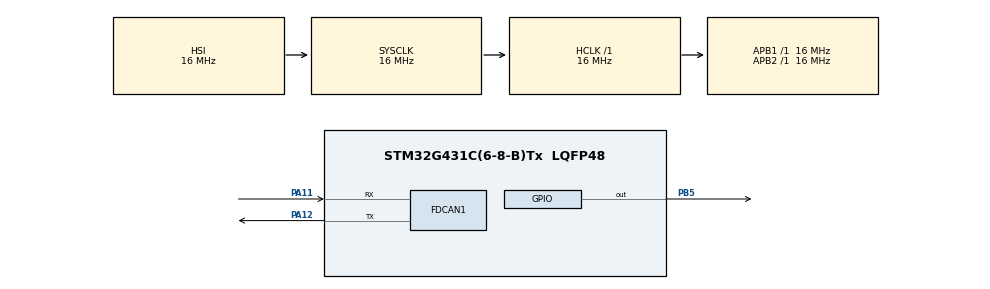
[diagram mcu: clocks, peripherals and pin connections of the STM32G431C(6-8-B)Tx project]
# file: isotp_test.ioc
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FDCAN1.AutoRetransmission=ENABLE
FDCAN1.CalculateBaudRateNominal=500000
FDCAN1.CalculateTimeBitNominal=2000
FDCAN1.CalculateTimeQuantumNominal=62.5
FDCAN1.DataSyncJumpWidth=15
FDCAN1.DataTimeSeg1=16
FDCAN1.DataTimeSeg2=15
FDCAN1.NominalPrescaler=1
FDCAN1.NominalSyncJumpWidth=2
FDCAN1.NominalTimeSeg1=29
FDCAN1.NominalTimeSeg2=2
Mcu.Family=STM32G4
Mcu.Name=STM32G431C(6-8-B)Tx
Mcu.Package=LQFP48
NVIC.FDCAN1_IT0_IRQn=true\:0\:0\:false\:false\:true\:true\:true\:true
NVIC.PriorityGroup=NVIC_PRIORITYGROUP_4
PA11.Mode=FDCAN_Activate
PA11.Signal=FDCAN1_RX
PA12.Mode=FDCAN_Activate
PA12.Signal=FDCAN1_TX
PB5.Signal=GPIO_Output
ProjectManager.HeapSize=0x200
ProjectManager.StackSize=0x400
ProjectManager.TargetToolchain=CMake
RCC.AHBFreq_Value=16000000
RCC.APB1Freq_Value=16000000
RCC.APB1TimFreq_Value=16000000
RCC.APB2Freq_Value=16000000
RCC.APB2TimFreq_Value=16000000
RCC.CortexFreq_Value=16000000
RCC.EXTERNAL_CLOCK_VALUE=12288000
RCC.HCLKFreq_Value=16000000
RCC.HSE_VALUE=8000000
RCC.HSI48_VALUE=48000000
RCC.HSI_VALUE=16000000
RCC.LSE_VALUE=32768
RCC.SYSCLKFreq_VALUE=16000000
RCC.USBFreq_Value=64000000
RCC.VCOOutputFreq_Value=128000000
VP_SYS_VS_DBSignals.Mode=DisableDeadBatterySignals
board=custom

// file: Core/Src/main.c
/* USER CODE BEGIN Header */
/**
  ******************************************************************************
  * @file           : main.c
  * @brief          : Main program body
  ******************************************************************************
  * @attention
  *
  * Copyright (c) 2026 STMicroelectronics.
  * All rights reserved.
  *
  * This software is licensed under terms that can be found in the LICENSE file
  * in the root directory of this software component.
  * If no LICENSE file comes with this software, it is provided AS-IS.
  *
  ******************************************************************************
  */
/* USER CODE END Header */
#include "main.h"
#include "fdcan.h"
#include "gpio.h"

/* USER CODE BEGIN Includes */
#include <string.h>
#include "drivers/can_driver.h"
#include "drivers/isotp.h"
#include "drivers/flash_driver.h"
#include "config/can_config.h"
#include "config/errno.h"
/* USER CODE END Includes */

void SystemClock_Config(void);

int main(void)
{

  /* MCU Configuration--------------------------------------------------------*/

  /* Reset of all peripherals, Initializes the Flash interface and the Systick. */
  HAL_Init();

  /* Configure the system clock */
  SystemClock_Config();

  /* Initialize all configured peripherals */
  MX_GPIO_Init();
  MX_FDCAN1_Init();
  /* USER CODE BEGIN 2 */

  // ================= initialise the stack
    sr_errno_t retval;
    sr_fdcan_handle_t fd_handle1;

    sr_fdcan_config_t cfg = {
        .fifo_overwrite=FDCAN_RX_FIFO_BLOCKING,
        .tx_id_type=FDCAN_STANDARD_ID,
        .tx_brs=FDCAN_FRAME_FD_NO_BRS,
        .tx_frame_format=FDCAN_CLASSIC_CAN,
        .tx_event_fifo_control=FDCAN_NO_TX_EVENTS
    };

    retval = sr_fdcan_config(&fd_handle1, &hfdcan1, &cfg);
    if (retval != SR_OK) {
        for(int i = 0; i < 5; i++) {
            HAL_GPIO_TogglePin(GPIOB, GPIO_PIN_5);
            HAL_Delay(1000);
            HAL_GPIO_TogglePin(GPIOB, GPIO_PIN_5);
            HAL_Delay(1000);
        }
        return 1;
    }
    retval = sr_fdcan_filter_add(&fd_handle1, FDCAN_FILTER_RANGE, FDCAN_FILTER_TO_RXFIFO0, ISOTP_RX_ID, ISOTP_RX_ID);
    if (retval != SR_OK) {
        for(int i = 0; i < 5; i++) {
            HAL_GPIO_TogglePin(GPIOB, GPIO_PIN_5);
            HAL_Delay(1000);
            HAL_GPIO_TogglePin(GPIOB, GPIO_PIN_5);
            HAL_Delay(1000);
        }
        return 1;
    }
    if (HAL_FDCAN_Start(&hfdcan1) != HAL_OK) {
        for(int i = 0; i < 5; i++) {
            HAL_GPIO_TogglePin(GPIOB, GPIO_PIN_5);
            HAL_Delay(1000);
            HAL_GPIO_TogglePin(GPIOB, GPIO_PIN_5);
            HAL_Delay(1000);
        }
        return 1;
    }
    sr_isotp_init(&fd_handle1, ISOTP_FORMAT_NORMAL);
  /* USER CODE END 2 */

  /* Infinite loop */
  /* USER CODE BEGIN WHILE */
  uint8_t rx_buffer[2048];
  uint32_t bytes_received;
  while (1)
  {
    /* USER CODE END WHILE */

    /* USER CODE BEGIN 3 */
    // ===================== START SERVER
    retval = sr_isotp_rx(rx_buffer, 2048, &bytes_received);

    if (retval == SR_OK) {
        char msg_recv[20];
        memcpy(msg_recv, rx_buffer, 20);
        char msg_send[15] = "brochachowacho";
        retval = sr_isotp_tx((const uint8_t*)msg_send, 15);
        if (retval != SR_OK) {
            HAL_GPIO_TogglePin(GPIOB, GPIO_PIN_5);
            HAL_Delay(1000);
            HAL_GPIO_TogglePin(GPIOB, GPIO_PIN_5);
            HAL_Delay(1000);
        }
    }
}
  /* USER CODE END 3 */
}

void SystemClock_Config(void)
{
  RCC_OscInitTypeDef RCC_OscInitStruct = {0};
  RCC_ClkInitTypeDef RCC_ClkInitStruct = {0};

  /** Configure the main internal regulator output voltage
  */
  HAL_PWREx_ControlVoltageScaling(PWR_REGULATOR_VOLTAGE_SCALE1);

  /** Initializes the RCC Oscillators according to the specified parameters
  * in the RCC_OscInitTypeDef structure.
  */
  RCC_OscInitStruct.OscillatorType = RCC_OSCILLATORTYPE_HSI;
  RCC_OscInitStruct.HSIState = RCC_HSI_ON;
  RCC_OscInitStruct.HSICalibrationValue = RCC_HSICALIBRATION_DEFAULT;
  RCC_OscInitStruct.PLL.PLLState = RCC_PLL_NONE;
  if (HAL_RCC_OscConfig(&RCC_OscInitStruct) != HAL_OK)
  {
    Error_Handler();
  }

  /** Initializes the CPU, AHB and APB buses clocks
  */
  RCC_ClkInitStruct.ClockType = RCC_CLOCKTYPE_HCLK|RCC_CLOCKTYPE_SYSCLK
                              |RCC_CLOCKTYPE_PCLK1|RCC_CLOCKTYPE_PCLK2;
  RCC_ClkInitStruct.SYSCLKSource = RCC_SYSCLKSOURCE_HSI;
  RCC_ClkInitStruct.AHBCLKDivider = RCC_SYSCLK_DIV1;
  RCC_ClkInitStruct.APB1CLKDivider = RCC_HCLK_DIV1;
  RCC_ClkInitStruct.APB2CLKDivider = RCC_HCLK_DIV1;

  if (HAL_RCC_ClockConfig(&RCC_ClkInitStruct, FLASH_LATENCY_0) != HAL_OK)
  {
    Error_Handler();
  }
}

void Error_Handler(void)
{
  __disable_irq();
  while (1)
  {
  }
}
